AUTOSAR XML (schema 00046)
package /Composition_Lab
  sender receiver interface SRI_LightControl
    data LightControl: type=uint32
  sender receiver interface LightActuate
    data LightActuate: type=uint32
  sensor actuator sw component type LightControlStatus_SWC
    provide port PP_SR_LightActuate: provided-interface=SRI_LightControl
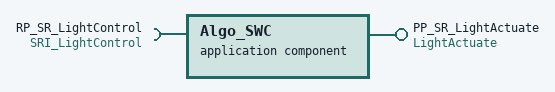
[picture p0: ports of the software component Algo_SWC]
  application sw component type Algo_SWC
    require port RP_SR_LightControl: provided-interface=SRI_LightControl
    provide port PP_SR_LightActuate: provided-interface=LightActuate
  application sw component type LightActuate_SWC
    require port RP_SR_LightActuate: required-interface=SRI_LightActuate
  composition sw component type SW_Composite1
    provide port PP_SR_LightActuate_Comp: provided-interface=LightActuate
    component LC_SA_SWC1: type=LightControlStatus_SWC
    component LA_SWC2: type=Algo_SWC
    connectors delegation-sw-connector={inner-port=LA_SWC2.PP_SR_LightActuate, outer-port=PP_SR_LightActuate_Comp}:
      connect LC_SA_SWC1.PP_SR_LightActuate -> LA_SWC2.RP_SR_LightControl
  composition sw component type TopLevel_CompositeSWC
    component SW_Composite1_Instance: type=SW_Composite1
    component LightActuate_SWC3: type=LightActuate_SWC
    connect SW_Composite1_Instance.PP_SR_LightActuate_Comp -> LightActuate_SWC3.RP_SR_LightActuate
